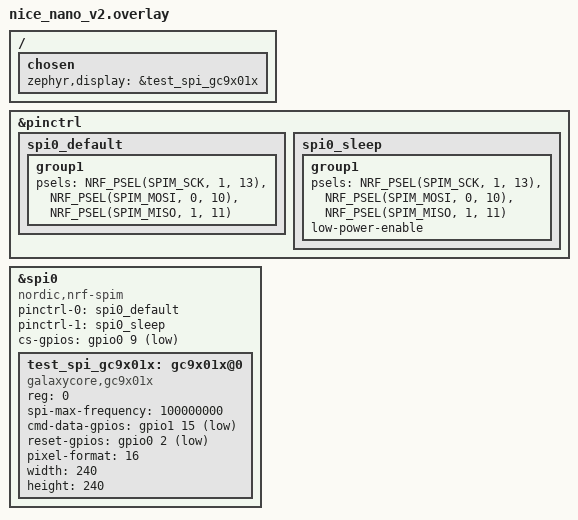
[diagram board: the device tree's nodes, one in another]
/*
 * nRF52840_mdk            ST7789V (240x240)
 *
 * P0.28 (RESET)            RES
 * P0.29 (D5)            DC (DATA/CMD)
 * P0.27 (SCK)            SCL
 * P0.26 (MOSI)            SDA
 */

&pinctrl {
	spi0_default: spi0_default {
		group1 {
			psels = <NRF_PSEL(SPIM_SCK, 1, 13)>,
			        <NRF_PSEL(SPIM_MOSI, 0, 10)>,
			        <NRF_PSEL(SPIM_MISO, 1, 11)>;
		};
	};

	spi0_sleep: spi0_sleep {
		group1 {
			psels = <NRF_PSEL(SPIM_SCK, 1, 13)>,
			        <NRF_PSEL(SPIM_MOSI, 0, 10)>,
			        <NRF_PSEL(SPIM_MISO, 1, 11)>;
			low-power-enable;
		};
	};
};

&spi0 {
	compatible = "nordic,nrf-spim";
	status = "okay";
	pinctrl-0 = <&spi0_default>;
	pinctrl-1 = <&spi0_sleep>;
	pinctrl-names = "default", "sleep";
	cs-gpios = <&gpio0 9 GPIO_ACTIVE_LOW>;

	test_spi_gc9x01x: gc9x01x@0 {
		compatible = "galaxycore,gc9x01x";
		reg = <0>;
		spi-max-frequency = <100000000>;
		cmd-data-gpios = <&gpio1 15 GPIO_ACTIVE_LOW>;
		reset-gpios = <&gpio0 2 GPIO_ACTIVE_LOW>;
		pixel-format = <16>;
		width = <240>;
		height = <240>;
	};
};

/ {
	chosen {
		zephyr,display = &test_spi_gc9x01x;
	};
};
